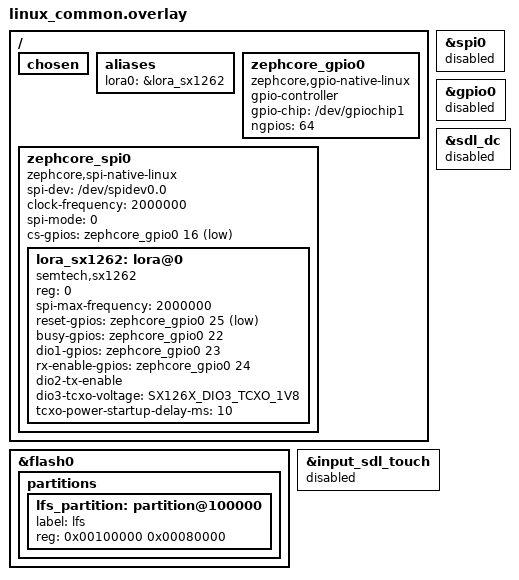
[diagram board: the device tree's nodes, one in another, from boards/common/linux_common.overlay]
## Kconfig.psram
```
# SPDX-License-Identifier: Apache-2.0
#
# DT-driven PSRAM auto-enable for ESP32 boards.
#
# Upstream Zephyr's esp32*_wroom_n*r*.dtsi files override psram0 size when
# the chip variant has PSRAM stuffed (R-suffix in the Espressif part number).
# We auto-enable PSRAM whenever the DTS size is non-zero — the upstream
# Kconfig.spiram then auto-reads ESP_SPIRAM_SIZE from the same DT property.
#
# Boards without PSRAM include a non-R-suffix dtsi (e.g. esp32s3_wroom_n8),
# which leaves psram0 at size = 0 — auto-detect leaves PSRAM off for them.
# ESP32-C3 and ESP32-C6 are outside Kconfig.spiram's SOC gate entirely, so
# this symbol doesn't exist on those builds — no effect.
#
# Mode (QUAD vs OCT) cannot be auto-picked here: upstream Kconfig.spiram
# sets an unconditional `default SPIRAM_MODE_QUAD` on the choice, which wins
# over any conditional default we'd add. ESP32-S3 R8 boards (8 MB OPI octal
# PSRAM) must set CONFIG_SPIRAM_MODE_OCT=y in their board.conf. R2 boards
# (2 MB QSPI quad) need nothing — QUAD is the upstream default.

config ESP_SPIRAM
	default y if (SOC_SERIES_ESP32 || SOC_SERIES_ESP32S2 || SOC_SERIES_ESP32S3 || SOC_SERIES_ESP32C5) && \
		"$(dt_node_int_prop_int,$(dt_nodelabel_path,psram0),size)" != 0
```

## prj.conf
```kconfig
# ZephCore - Main Project Configuration
#
# This file contains ONLY console/logging setup and includes common configs.
# Platform-specific configs are in boards/common/<platform>_common.conf
# Board-specific configs (pins only) are in boards/<board>.conf
#
# Include hierarchy:
#   prj.conf (this file - logging/console)
#   → boards/common/zephcore_common.conf (app features, crypto, sensors)
#   → boards/common/<platform>_common.conf (BLE, flash, storage)
#   → boards/<board>.conf (pins, board-specific features)

# ========== Console & Logging ==========
CONFIG_CONSOLE=y
CONFIG_UART_CONSOLE=y
CONFIG_UART_INTERRUPT_DRIVEN=y
CONFIG_RING_BUFFER=y

# Production by default — add boards/common/debug.conf to enable logging.
CONFIG_LOG=n
CONFIG_ASSERT=n
CONFIG_USE_SEGGER_RTT=n
CONFIG_THREAD_NAME=n

# Reboot on any fatal error (stack overflow, hard fault, etc.) instead of
# spinning forever. Asserts are disabled so they won't reach here, but all
# other fatal paths (k_panic, CPU exceptions) still get a clean reboot.
CONFIG_RESET_ON_FATAL_ERROR=y

# ========== Power Management ==========
# Note: nRF52840 automatically uses WFI (Wait For Interrupt) in idle thread.
# Power savings come from event-driven design: CPU sleeps in WFI whenever
# k_event_wait() blocks. GPS standby uses GPIO power control (not PM_DEVICE).
# CONFIG_PM_DEVICE intentionally DISABLED — it enables SYSTEM_MANAGED PM which
# auto-suspends all devices (including GNSS) during idle, calling modem_chat
# from an unexpected context and potentially deadlocking the system.
```

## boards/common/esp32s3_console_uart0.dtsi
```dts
/*
 * Reroute console + shell off USB Serial/JTAG onto uart0 (physical TX/RX).
 *
 * ESP32-S3 USB Serial/JTAG shares the D+/D- pins with USB OTG and only one
 * controller can own the port at a time.  Boards that default their console to
 * USB Serial/JTAG include this alongside esp32s3_usb_otg.dtsi so that, when
 * esp32s3_usb.conf disables USB Serial/JTAG and hands the port to USB OTG, the
 * console still has a home.  Boards with a dedicated UART console (e.g. Heltec)
 * do not need this.
 *
 * uart0 is disabled by default in the ESP32-S3 SoC dtsi, so we enable it and
 * pin it to the chip's ROM-default UART0 pads (GPIO43 TX / GPIO44 RX) — the
 * same pins Heltec uses.  Without this the console would point at a disabled,
 * un-pinned node and produce no output at all.
 */
#include <zephyr/dt-bindings/pinctrl/esp-pinctrl-common.h>
#include <zephyr/dt-bindings/pinctrl/esp32s3-pinctrl.h>
#include <zephyr/dt-bindings/pinctrl/esp32s3-gpio-sigmap.h>

&pinctrl {
	uart0_default: uart0_default {
		group1 {
			pinmux = <UART0_TX_GPIO43>;
			output-high;
		};
		group2 {
			pinmux = <UART0_RX_GPIO44>;
			bias-pull-up;
		};
	};
};

&uart0 {
	status = "okay";
	current-speed = <115200>;
	pinctrl-0 = <&uart0_default>;
	pinctrl-names = "default";
};

/ {
	chosen {
		zephyr,console    = &uart0;
		zephyr,shell-uart = &uart0;
	};
};
```

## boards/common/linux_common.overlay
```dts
/*
 * SPDX-License-Identifier: Apache-2.0
 *
 * ZephCore native Linux DT overlay (auto-paired with linux_common.conf).
 *
 * Disables the native_sim emulated GPIO/SPI controllers and adds our
 * libgpiod/spidev-backed native_linux versions, with an SX1262 child
 * node on the SPI bus.
 *
 * Generic defaults below match the Femtofox SX1262 wiring. Override per
 * device by adding boards/common/<device>.conf + .overlay via
 * EXTRA_CONF_FILE, or use --lora-* command-line args at runtime.
 */

#include <zephyr/dt-bindings/gpio/gpio.h>
#include <zephyr/dt-bindings/lora/sx126x.h>

/* Disable native_sim emulated controllers (replaced below). */
&spi0 {
	status = "disabled";
};

&gpio0 {
	status = "disabled";
};

/* LittleFS on native_sim's simulated flash.
 * The native_sim board DTS allocates the first 1MB (0x0..0xfffff) for
 * MCUBoot + OTA slots. The second half (0x100000..0x1fffff = 1MB) is unused.
 * Use 512KB of it for LittleFS — 128 × 4KB blocks, plenty for identity,
 * prefs, contacts, and channels.
 * The sim-flash is in-memory (lost on exit); add
 * CONFIG_FLASH_SIMULATOR_STATS_FILE for file-backed persistence. */
&flash0 {
	partitions {
		lfs_partition: partition@100000 {
			label = "lfs";
			reg = <0x00100000 0x00080000>; /* 512 KB */
		};
	};
};

#include "filesystem.dtsi"

/* Disable the SDL emulated display + touch (we don't use them and the
 * SDL2 dev library isn't a useful dep on a headless SBC). */
&sdl_dc {
	status = "disabled";
};

&input_sdl_touch {
	status = "disabled";
};

/* Drop the chosen zephyr,display node so HAS_SDL doesn't get selected.
 * Also drop the led0 alias — native_sim's base DTS attaches it to the
 * emulated gpio0 that we just disabled, which would otherwise cause a
 * dangling DEVICE_DT_GET in helpers/ui/ui_common.c. */
/ {
	chosen {
		/delete-property/ zephyr,display;
		/delete-property/ zephyr,touch;
	};
	aliases {
		/delete-property/ led0;
	};
};

/ {
	/delete-node/ leds;
};

/ {
	aliases {
		/* The mesh adapter reads lora0 alias to bind the SX126x driver. */
		lora0 = &lora_sx1262;
	};

	/* libgpiod v2 GPIO controller bound to a host /dev/gpiochipX. */
	zephcore_gpio0: zephcore_gpio0 {
		status = "okay";
		compatible = "zephcore,gpio-native-linux";
		gpio-controller;
		gpio-chip = "/dev/gpiochip1";
		ngpios = <64>;
		#gpio-cells = <2>;
	};

	/* spidev-backed SPI bus on /dev/spidev0.0 with one SX1262 child. */
	zephcore_spi0: zephcore_spi0 {
		status = "okay";
		compatible = "zephcore,spi-native-linux";
		spi-dev = "/dev/spidev0.0";
		clock-frequency = <2000000>;
		spi-mode = <0>;
		#address-cells = <1>;
		#size-cells = <0>;
		/* CS line: GPIO 16 on chip 1 = GPIO48 = 1C0 (Femtofox default). */
		cs-gpios = <&zephcore_gpio0 16 GPIO_ACTIVE_LOW>;

		lora_sx1262: lora@0 {
			compatible = "semtech,sx1262";
			reg = <0>;
			spi-max-frequency = <2000000>;
			/* Femtofox defaults; overridden by per-device overlays. */
			reset-gpios = <&zephcore_gpio0 25 GPIO_ACTIVE_LOW>;
			busy-gpios  = <&zephcore_gpio0 22 GPIO_ACTIVE_HIGH>;
			dio1-gpios  = <&zephcore_gpio0 23 GPIO_ACTIVE_HIGH>;
			rx-enable-gpios = <&zephcore_gpio0 24 GPIO_ACTIVE_HIGH>;
			dio2-tx-enable;
			dio3-tcxo-voltage = <SX126X_DIO3_TCXO_1V8>;
			tcxo-power-startup-delay-ms = <10>;
		};
	};
};
```

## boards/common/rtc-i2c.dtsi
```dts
/*
 * Common I2C Real-Time-Clock descriptors for ZephCore
 * SPDX-License-Identifier: Apache-2.0
 *
 * OPT-IN: include this inside an &i2cN { ... } block ONLY on boards that
 * physically have a battery/cap-backed RTC. Kept separate from
 * sensors-i2c.dtsi because these declare fixed I2C addresses (0x68/0x51/
 * 0x52/0x32) that collide with common parts — an IMU/accelerometer sits at
 * 0x68 (same as DS3231). Including this on a board without an RTC would risk
 * a devicetree unit-address clash and a runtime mis-probe, so it is opt-in.
 *
 * Usage (board overlay/dts, alongside the sensors include):
 *   &i2c0 {
 *       #include "../../common/sensors-i2c.dtsi"
 *       #include "../../common/rtc-i2c.dtsi"
 *   };
 *
 * These bind NO Zephyr RTC driver — they're data-only descriptors the
 * boot-time auto-discovery (adapters/clock/ZephyrRTCDiscover.c) probes via
 * raw I2C to restore wall-clock time at boot. A chip that isn't actually
 * present fails the probe and is skipped. One chip per I2C address:
 *
 *  Chip      │ Addr │ Also covers (same regs)
 *  ──────────┼──────┼─────────────────────────
 *  DS3231    │ 0x68 │ DS1307, DS3232
 *  PCF8563   │ 0x51 │ —   (PCF85063A is 0x51 too but differs — override)
 *  RV3028    │ 0x52 │ —
 *  RX8130CE  │ 0x32 │ —   (RV8803 is 0x32 too but differs — override)
 *
 * status-reg 0xFF means the power-loss flag is in the seconds byte. A board
 * with a same-address variant should /delete-node/ the conflicting one and
 * add its own in the board overlay.
 */

rtc_ds3231: rtc-ds3231@68 {
	compatible = "zephcore,rtc-i2c";
	reg = <0x68>;
	time-reg = <0x00>;
	date-index = <4>;
	status-reg = <0x0F>;   /* control/status */
	status-mask = <0x80>;  /* OSF — oscillator stopped */
};

rtc_pcf8563: rtc-pcf8563@51 {
	compatible = "zephcore,rtc-i2c";
	reg = <0x51>;
	time-reg = <0x02>;
	date-index = <3>;      /* PCF8563 puts date before weekday */
	status-reg = <0xFF>;   /* flag is in the seconds byte */
	status-mask = <0x80>;  /* VL — clock integrity not guaranteed */
};

rtc_rv3028: rtc-rv3028@52 {
	compatible = "zephcore,rtc-i2c";
	reg = <0x52>;
	time-reg = <0x00>;
	date-index = <4>;
	status-reg = <0x0e>;   /* status */
	status-mask = <0x01>;  /* PORF — power-on reset */
};

rtc_rx8130ce: rtc-rx8130ce@32 {
	compatible = "zephcore,rtc-i2c";
	reg = <0x32>;
	time-reg = <0x10>;
	date-index = <4>;
	status-reg = <0x1d>;   /* flag */
	status-mask = <0x02>;  /* VLF — voltage low */
};
```

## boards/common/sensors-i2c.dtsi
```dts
/*
 * Common I2C Sensor Definitions for ZephCore
 * SPDX-License-Identifier: Apache-2.0
 *
 * Include this file inside an &i2cN { ... } block to define all
 * supported sensor nodes on that bus.  Sensors that are not physically
 * present will fail device_is_ready() at runtime and be gracefully
 * skipped by ZephyrEnvSensors — no harm, no extra current draw.
 *
 * Usage (board overlay):
 *   &i2c0 {
 *       #include "../../common/sensors-i2c.dtsi"
 *   };
 *
 * ─── Environment Sensors (temperature / humidity / pressure) ───
 *
 *  Sensor      │ Address │ Compatible          │ Channels
 *  ────────────┼─────────┼─────────────────────┼────────────────────
 *  SHTC3       │ 0x70    │ sensirion,shtcx     │ temp + humidity
 *  AHT20       │ 0x38    │ aosong,aht20        │ temp + humidity
 *  DHT20       │ 0x38    │ aosong,dht20        │ temp + humidity
 *  AM2301B     │ 0x38    │ aosong,am2301b      │ temp + humidity
 *  SHT4x       │ 0x44    │ sensirion,sht4x     │ temp + humidity
 *  SHT3xD      │ 0x44    │ sensirion,sht3xd    │ temp + humidity
 *  BME280      │ 0x76    │ bosch,bme280        │ temp + humidity + pressure
 *  BME680      │ 0x76    │ bosch,bme680        │ temp + humidity + pressure + gas
 *  BMP280      │ 0x77    │ bosch,bme280        │ temp + pressure (BME280 driver)
 *  BMP388      │ 0x77    │ bosch,bmp388        │ temp + pressure
 *  LPS22HB     │ 0x5C    │ st,lps22hb-press    │ pressure + temp
 *
 *  Note: AHT20/DHT20/AM2301B share address 0x38 — only one can be
 *  defined.  We use AHT20 as the default (same driver handles all).
 *
 *  Note: SHT4x and SHT3xD share address 0x44 — only one can be
 *  defined.  We use SHT4x as the default (more common in new designs).
 *
 *  Note: BME280 and BME680 share address 0x76 — only one can be
 *  defined.  We use BME280 as default (its driver also handles BMP280).
 *  Boards with BME680 should override this node in their overlay.
 *
 *  Note: BMP280 uses the BME280 driver (same register set), at alt
 *  address 0x77.  BMP388 also uses 0x77.  Only one can be defined —
 *  we use BMP388 since it's the newer part.
 *
 * ─── Power Monitor Sensors (voltage / current / power) ───
 *
 *  Sensor      │ Address │ Compatible   │ Channels
 *  ────────────┼─────────┼──────────────┼────────────────────
 *  INA219      │ 0x40    │ ti,ina219    │ 1ch: V + I + P
 *  INA3221     │ 0x40    │ ti,ina3221   │ 3ch: V + I + P
 *  INA226      │ 0x40    │ ti,ina226    │ 1ch: V + I + P
 *
 *  Note: INA219, INA3221, and INA226 share address 0x40 — only one
 *  can be defined at a time.  Boards with a specific INA chip should
 *  delete the others or override this file.
 *  We define INA219 as default (most common single-channel monitor).
 */

/* ── Temperature / Humidity ── */

shtc3: shtc3@70 {
	compatible = "sensirion,shtcx";
	reg = <0x70>;
	measure-mode = "normal";
	clock-stretching;
};

aht20: aht20@38 {
	compatible = "aosong,aht20";
	reg = <0x38>;
};

sht4x: sht4x@44 {
	compatible = "sensirion,sht4x";
	reg = <0x44>;
	repeatability = <2>;  /* high */
};

/* ── Combo: Temperature + Humidity + Pressure ── */

bme280: bme280@76 {
	compatible = "bosch,bme280";
	reg = <0x76>;
};

/* ── Pressure (standalone) ── */

lps22hb: lps22hb@5c {
	compatible = "st,lps22hb-press";
	reg = <0x5c>;
};

bmp388: bmp388@77 {
	compatible = "bosch,bmp388";
	reg = <0x77>;
};

/* ── Power Monitors ── */

ina219: ina219@40 {
	compatible = "ti,ina219";
	reg = <0x40>;
	shunt-milliohm = <100>;
	lsb-microamp = <10>;
};

/* Real-time clocks are NOT here — they live in the opt-in "rtc-i2c.dtsi"
 * (included only by boards that physically have a battery-backed RTC), so
 * their fixed addresses (0x68/0x51/0x52/0x32) can't collide with an IMU or
 * other peripheral on boards that don't. */
```

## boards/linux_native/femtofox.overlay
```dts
/*
 * SPDX-License-Identifier: Apache-2.0
 *
 * Femtofox (Luckfox Pico Mini RV1103 + Ebyte E22-900M30S, SX1262 TCXO) wiring.
 * Auto-paired with femtofox.conf. Defines the native_linux SPI/GPIO controllers
 * and the SX1262 radio node on top of the platform infra in linux_common.overlay.
 *
 * Pins match the meshtasticd Femtofox profile (femtofox_SX1262_TCXO.yaml):
 * gpiochip1, CS=16/GPIO48, BUSY=22/GPIO54, DIO1=23/GPIO55, RESET=25/GPIO57,
 * RXEN=24/GPIO56. DIO2 drives the RF switch, DIO3 powers a 1.8V TCXO.
 */

#include <zephyr/dt-bindings/gpio/gpio.h>
#include <zephyr/dt-bindings/lora/sx126x.h>

/ {
	aliases {
		/* The mesh adapter reads lora0 to bind the SX126x driver. */
		lora0 = &lora_sx1262;
	};

	/* GPIO V2 chardev controller bound to /dev/gpiochip1. */
	zephcore_gpio0: zephcore_gpio0 {
		status = "okay";
		compatible = "zephcore,gpio-native-linux";
		gpio-controller;
		gpio-chip = "/dev/gpiochip1";
		ngpios = <64>;
		#gpio-cells = <2>;
	};

	/* spidev-backed SPI bus on /dev/spidev0.0 with one SX1262 child. */
	zephcore_spi0: zephcore_spi0 {
		status = "okay";
		compatible = "zephcore,spi-native-linux";
		spi-dev = "/dev/spidev0.0";
		clock-frequency = <2000000>;
		spi-mode = <0>;
		#address-cells = <1>;
		#size-cells = <0>;
		/* CS: gpiochip1 offset 16 = GPIO48. */
		cs-gpios = <&zephcore_gpio0 16 GPIO_ACTIVE_LOW>;

		lora_sx1262: lora@0 {
			compatible = "semtech,sx1262";
			reg = <0>;
			spi-max-frequency = <2000000>;
			reset-gpios = <&zephcore_gpio0 25 GPIO_ACTIVE_LOW>;
			busy-gpios  = <&zephcore_gpio0 22 GPIO_ACTIVE_HIGH>;
			dio1-gpios  = <&zephcore_gpio0 23 GPIO_ACTIVE_HIGH>;
			rx-enable-gpios = <&zephcore_gpio0 24 GPIO_ACTIVE_HIGH>;
			dio2-tx-enable;
			dio3-tcxo-voltage = <SX126X_DIO3_TCXO_1V8>;
			tcxo-power-startup-delay-ms = <5>;
		};
	};
};
```

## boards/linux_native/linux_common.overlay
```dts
/*
 * SPDX-License-Identifier: Apache-2.0
 *
 * ZephCore native Linux PLATFORM overlay (auto-paired with linux_common.conf,
 * applied automatically for BOARD=native_sim).
 *
 * Platform infrastructure ONLY — it disables native_sim's emulated SPI/GPIO
 * and SDL display, and sets up the LittleFS partition. The radio wiring and
 * the native_linux SPI/GPIO controller nodes live in the per-device preset
 * overlay (femtofox.overlay, rak6421.overlay, rak6421_pi5.overlay).
 *
 * You MUST pass a device preset via EXTRA_CONF_FILE, e.g.
 *   -DEXTRA_CONF_FILE="boards/linux_native/femtofox.conf"
 * A bare `-b native_sim` build with no device preset has no SX1262 node and
 * will fail to link the radio adapter (no `lora0` alias).
 */

/* Disable the native_sim emulated controllers — each device preset adds its
 * own zephcore_spi0 / zephcore_gpio0 backed by real /dev/spidev* + /dev/gpiochip*. */
&spi0 {
	status = "disabled";
};

&gpio0 {
	status = "disabled";
};

/* LittleFS on native_sim's simulated flash.
 * The native_sim board DTS allocates the first 1MB (0x0..0xfffff) for
 * MCUBoot + OTA slots. The second half (0x100000..0x1fffff = 1MB) is unused;
 * use 512KB of it for LittleFS — 128 × 4KB blocks, plenty for identity,
 * prefs, contacts, and channels.
 * The sim-flash is FILE-BACKED on native_sim (ARCH_POSIX): it persists across
 * restarts in meshcore_settings_<hostname>.bin in the binary's working dir
 * (see patches/zephyr/0008-flash-sim-per-node-file.patch). Pass --flash=<path>
 * to override, or --flash_in_ram to make it ephemeral. */
&flash0 {
	partitions {
		lfs_partition: partition@100000 {
			label = "lfs";
			reg = <0x00100000 0x00080000>; /* 512 KB */
		};
	};
};

#include "../common/filesystem.dtsi"

/* Disable the SDL emulated display + touch (headless SBC; the SDL2 dev library
 * isn't a useful dep, and HAS_SDL would otherwise get selected). */
&sdl_dc {
	status = "disabled";
};

&input_sdl_touch {
	status = "disabled";
};

/ {
	chosen {
		/delete-property/ zephyr,display;
		/delete-property/ zephyr,touch;
	};
	aliases {
		/* native_sim's base DTS attaches led0 to the emulated gpio0 we just
		 * disabled; drop it so helpers/ui/ui_common.c has no dangling
		 * DEVICE_DT_GET. */
		/delete-property/ led0;
	};
};

/ {
	/delete-node/ leds;
};
```

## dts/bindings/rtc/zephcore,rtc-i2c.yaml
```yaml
# SPDX-License-Identifier: Apache-2.0
#
# Data-only descriptor for an I2C RTC chip read by ZephyrRTCDiscover
# (adapters/clock/ZephyrRTCDiscover.c). This binds NO Zephyr RTC driver —
# the chip is accessed with raw I2C using the register layout described by
# the properties below. This keeps the boot-time RTC restore compact
# (~2-3 KB total, "Path B") instead of pulling in the full RTC subsystem.
#
# All supported chips use a 7-byte BCD time block (sec, min, hour, then
# weekday/date, month, year) starting at "time-reg". Only the day-of-month
# byte offset varies between parts, captured by "date-index".

description: ZephCore data-only I2C RTC descriptor (raw-I2C, no Zephyr RTC driver)

compatible: "zephcore,rtc-i2c"

include: [i2c-device.yaml]

properties:
  time-reg:
    type: int
    required: true
    description: Register address of the seconds byte (start of the 7-byte BCD block).

  date-index:
    type: int
    required: true
    description: >
      Byte offset of the day-of-month within the 7-byte block. 4 for chips
      ordered sec/min/hour/weekday/date/month/year (DS3231, RV3028, RX8130CE);
      3 for PCF8563 which swaps to sec/min/hour/date/weekday/month/year.

  status-reg:
    type: int
    required: true
    description: >
      Register holding the "time invalid / power was lost" flag. Use 0xFF to
      indicate the flag lives in the seconds byte itself (PCF8563 VL bit).

  status-mask:
    type: int
    required: true
    description: Bit mask within status-reg that means the held time is unreliable.
```

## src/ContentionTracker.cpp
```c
/*
 * SPDX-License-Identifier: Apache-2.0
 * Adaptive Contention Window — dupe-counting based delay estimation
 */

#include <mesh/ContentionTracker.h>
#include <mesh/Packet.h>
#include <string.h>

namespace mesh {

ContentionTracker::ContentionTracker()
	: _next_idx(0), _ema_x256(0), _finalized_count(0),
	  _last_retransmit_ms(0), _backoff_multiplier(DEFAULT_BACKOFF_MULT)
{
	memset(_ring, 0, sizeof(_ring));
}

/* FNV-1a over payload_type + first 8 payload bytes */
uint32_t ContentionTracker::computePacketHash32(const Packet *pkt)
{
	uint32_t h = 0x811c9dc5u; /* FNV-1a offset basis */
	uint8_t t = pkt->getPayloadType();
	h = (h ^ t) * 0x01000193u;
	int n = pkt->payload_len < 8 ? pkt->payload_len : 8;
	for (int i = 0; i < n; i++) {
		h = (h ^ pkt->payload[i]) * 0x01000193u;
	}
	return h;
}

int ContentionTracker::findEntry(uint32_t hash32) const
{
	for (int i = 0; i < RING_SIZE; i++) {
		if (_ring[i].active && _ring[i].hash32 == hash32) {
			return i;
		}
	}
	return -1;
}

void ContentionTracker::finalizeEntry(int idx)
{
	if (!_ring[idx].active) return;

	uint32_t sample_x256 = (uint32_t)_ring[idx].dupe_count << 8;

	int32_t diff = (int32_t)sample_x256 - (int32_t)_ema_x256;

	if (_finalized_count < WARMUP_PACKETS) {
		/* Warmup: seed EMA with fast convergence */
		if (_finalized_count == 0) {
			_ema_x256 = sample_x256;
		} else {
			_ema_x256 = (uint32_t)((int32_t)_ema_x256 + (diff >> 1));
		}
	} else {
		_ema_x256 = (uint32_t)((int32_t)_ema_x256 + (diff >> EMA_SHIFT));
	}

	_finalized_count++;
	_ring[idx].active = false;
}

void ContentionTracker::trackRetransmit(uint32_t hash32, uint32_t now_ms)
{
	_last_retransmit_ms = now_ms;

	/* Evict oldest if ring slot occupied */
	if (_ring[_next_idx].active) {
		finalizeEntry(_next_idx);
	}

	Entry &e = _ring[_next_idx];
	e.hash32 = hash32;
	e.first_seen_ms = now_ms;
	e.dupe_count = 0;
	e.reactive_added_ms = 0;
	e.active = true;

	_next_idx = (_next_idx + 1) % RING_SIZE;
}

bool ContentionTracker::recordDupeIfTracked(uint32_t hash32, uint32_t now_ms)
{
	int idx = findEntry(hash32);
	if (idx < 0) return false;

	Entry &e = _ring[idx];

	if (now_ms - e.first_seen_ms > WINDOW_MS) {
		finalizeEntry(idx);
		return false;
	}

	if (e.dupe_count < 255) {
		e.dupe_count++;
	}
	return true;
}

int ContentionTracker::extractDupeCount(uint32_t hash32)
{
	int idx = findEntry(hash32);
	if (idx < 0) return -1;
	int count = (int)_ring[idx].dupe_count;
	finalizeEntry(idx);  /* folds into EMA, marks inactive */
	return count;
}

uint16_t ContentionTracker::getReactiveHeadroom(uint32_t hash32, uint32_t airtime_ms) const
{
	int idx = findEntry(hash32);
	if (idx < 0) return 0;

	uint32_t per_dupe = (uint32_t)(_backoff_multiplier * (float)airtime_ms);
	if (per_dupe == 0) return 0;

	/* Effective cap: ~12 relay-slots (airtime-scaled), absolute ceiling REACTIVE_HARD_CAP_MS */
	uint32_t effective_cap = 12 * airtime_ms;
	if (effective_cap > REACTIVE_HARD_CAP_MS) effective_cap = REACTIVE_HARD_CAP_MS;

	if (_ring[idx].reactive_added_ms >= effective_cap) return 0;

	uint32_t remaining = effective_cap - _ring[idx].reactive_added_ms;
	if (per_dupe > remaining) per_dupe = remaining;
	return per_dupe > 0xFFFF ? 0xFFFF : (uint16_t)per_dupe;
}

void ContentionTracker::addReactiveExtension(uint32_t hash32, uint16_t added_ms)
{
	int idx = findEntry(hash32);
	if (idx < 0) return;

	uint32_t total = (uint32_t)_ring[idx].reactive_added_ms + added_ms;
	_ring[idx].reactive_added_ms = total > 0xFFFF ? 0xFFFF : (uint16_t)total;
}

void ContentionTracker::tick(uint32_t now_ms)
{
	for (int i = 0; i < RING_SIZE; i++) {
		if (_ring[i].active && now_ms - _ring[i].first_seen_ms > WINDOW_MS) {
			finalizeEntry(i);
		}
	}

	/* Decay EMA toward 0 if no retransmit in STALE_MS */
	if (_last_retransmit_ms != 0 && now_ms - _last_retransmit_ms > STALE_MS) {
		if (_ema_x256 > 0) {
			_ema_x256 -= _ema_x256 >> EMA_SHIFT;
		}
	}
}

float ContentionTracker::getContentionEstimate() const
{
	return (float)_ema_x256 / 256.0f;
}

float ContentionTracker::getFloodDelayFactor() const
{
	if (!isWarmedUp()) return 0.5f; /* conservative default before warmup */

	float est = getContentionEstimate();
	if (est <= 0.0f) return MIN_FLOOD_FACTOR;

	/* Arduino-like center near 0.5 in light contention, rising smoothly
	 * toward 0.8 as contention increases. */
	float factor = MIN_FLOOD_FACTOR + (MAX_FLOOD_FACTOR - MIN_FLOOD_FACTOR) *
		       (est / (est + FLOOD_EST_HALFPOINT));
	if (factor > MAX_FLOOD_FACTOR) factor = MAX_FLOOD_FACTOR;
	return factor;
}

} /* namespace mesh */
```

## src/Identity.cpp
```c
/*
 * SPDX-License-Identifier: Apache-2.0
 * ZephCore Identity - Ed25519 sign/verify (Monocypher backend)
 *
 * Backed by Monocypher (lib/monocypher). The persisted private key keeps the
 * historical 64-byte *expanded* layout — prv[0..31] = clamped SHA-512(seed)
 * scalar `a`, prv[32..63] = nonce prefix — so identities written by older
 * (orlp/ed25519) firmware load, sign, and key-exchange byte-for-byte unchanged.
 * Signing is built from Monocypher's low-level EdDSA primitives because the
 * stored expanded key carries no seed to feed the high-level API.
 */

#include <mesh/Identity.h>
#include <string.h>
#include <monocypher.h>
#include <monocypher-ed25519.h>

namespace mesh {

/* Expand a 32-byte seed into the stored 64-byte private key (orlp-compatible
 * layout): clamped SHA-512(seed)[0..31] || SHA-512(seed)[32..63]. */
static void expandSeed(uint8_t prv[PRV_KEY_SIZE], const uint8_t seed[SEED_SIZE])
{
	crypto_sha512(prv, seed, SEED_SIZE);
	prv[0]  &= 248;
	prv[31] &= 63;
	prv[31] |= 64;
}

/* Sign from the expanded key (no seed). RFC 8032 Ed25519 assembled from
 * Monocypher scalar/point primitives — byte-identical to the prior orlp
 * implementation (verified by known-answer tests). */
static void signExpanded(uint8_t sig[SIGNATURE_SIZE],
			 const uint8_t prv[PRV_KEY_SIZE],
			 const uint8_t pub[PUB_KEY_SIZE],
			 const uint8_t *msg, size_t msg_len)
{
	uint8_t r64[64], hram64[64], r[32], hram[32];
	crypto_sha512_ctx h;

	/* r = SHA-512(prefix || msg) mod L ; prefix = prv[32..63] */
	crypto_sha512_init(&h);
	crypto_sha512_update(&h, prv + 32, 32);
	crypto_sha512_update(&h, msg, msg_len);
	crypto_sha512_final(&h, r64);
	crypto_eddsa_reduce(r, r64);

	/* R = r·B -> sig[0..31] */
	crypto_eddsa_scalarbase(sig, r);

	/* hram = SHA-512(R || A || msg) mod L */
	crypto_sha512_init(&h);
	crypto_sha512_update(&h, sig, 32);
	crypto_sha512_update(&h, pub, 32);
	crypto_sha512_update(&h, msg, msg_len);
	crypto_sha512_final(&h, hram64);
	crypto_eddsa_reduce(hram, hram64);

	/* S = (hram·a + r) mod L ; a = prv[0..31] -> sig[32..63] */
	crypto_eddsa_mul_add(sig + 32, hram, prv, r);

	/* r / r64 are nonce material — leaking them leaks the private key. */
	crypto_wipe(r64, sizeof(r64));
	crypto_wipe(r, sizeof(r));
}

/* X25519 over Ed25519 keys: convert the peer's Edwards public key to its
 * Montgomery form, then scalar-multiply by our scalar (prv[0..31]). Raw
 * shared secret, no output hashing — matches the prior orlp key_exchange. */
static void calcECDH(uint8_t secret[CIPHER_KEY_SIZE * 2],
		     const uint8_t prv[PRV_KEY_SIZE],
		     const uint8_t other_pub[PUB_KEY_SIZE])
{
	uint8_t other_x[32];
	crypto_eddsa_to_x25519(other_x, other_pub);
	crypto_x25519(secret, prv, other_x);
}

Identity::Identity()
{
	memset(pub_key, 0, sizeof(pub_key));
}

Identity::Identity(const char *pub_hex)
{
	Utils::fromHex(pub_key, PUB_KEY_SIZE, pub_hex);
}

bool Identity::verify(const uint8_t *sig, const uint8_t *message, int msg_len) const
{
	return crypto_ed25519_check(sig, pub_key, message, (size_t)msg_len) == 0;
}

bool Identity::readFrom(const uint8_t *src, size_t len)
{
	if (len < PUB_KEY_SIZE) return false;
	memcpy(pub_key, src, PUB_KEY_SIZE);
	return true;
}

bool Identity::writeTo(uint8_t *dest, size_t max_len) const
{
	if (max_len < PUB_KEY_SIZE) return false;
	memcpy(dest, pub_key, PUB_KEY_SIZE);
	return true;
}

LocalIdentity::LocalIdentity()
{
	memset(prv_key, 0, sizeof(prv_key));
}

LocalIdentity::LocalIdentity(const char *prv_hex, const char *pub_hex) : Identity(pub_hex)
{
	Utils::fromHex(prv_key, PRV_KEY_SIZE, prv_hex);
}

LocalIdentity::LocalIdentity(RNG *rng)
{
	uint8_t seed[SEED_SIZE];
	rng->random(seed, SEED_SIZE);
	fromSeed(seed);
	Utils::secureZeroize(seed, sizeof(seed));
}

void LocalIdentity::fromSeed(const uint8_t seed[SEED_SIZE])
{
	expandSeed(prv_key, seed);
	crypto_eddsa_scalarbase(pub_key, prv_key);  /* pub = a·B */
}

bool LocalIdentity::validatePrivateKey(const uint8_t prv[64])
{
	uint8_t pub[32];
	crypto_eddsa_scalarbase(pub, prv);
	if (pub[0] == 0x00 || pub[0] == 0xFF) return false;

	const uint8_t test_client_prv[64] = {
		0x70, 0x65, 0xe1, 0x8f, 0xd9, 0xfa, 0xbb, 0x70,
		0xc1, 0xed, 0x90, 0xdc, 0xa1, 0x99, 0x07, 0xde,
		0x69, 0x8c, 0x88, 0xb7, 0x09, 0xea, 0x14, 0x6e,
		0xaf, 0xd9, 0x3d, 0x9b, 0x83, 0x0c, 0x7b, 0x60,
		0xc4, 0x68, 0x11, 0x93, 0xc7, 0x9b, 0xbc, 0x39,
		0x94, 0x5b, 0xa8, 0x06, 0x41, 0x04, 0xbb, 0x61,
		0x8f, 0x8f, 0xd7, 0xa8, 0x4a, 0x0a, 0xf6, 0xf5,
		0x70, 0x33, 0xd6, 0xe8, 0xdd, 0xcd, 0x64, 0x71
	};
	const uint8_t test_client_pub[32] = {
		0x1e, 0xc7, 0x71, 0x75, 0xb0, 0x91, 0x8e, 0xd2,
		0x06, 0xf9, 0xae, 0x04, 0xec, 0x13, 0x6d, 0x6d,
		0x5d, 0x43, 0x15, 0xbb, 0x26, 0x30, 0x54, 0x27,
		0xf6, 0x45, 0xb4, 0x92, 0xe9, 0x35, 0x0c, 0x10
	};

	uint8_t ss1[32], ss2[32];
	calcECDH(ss1, prv, test_client_pub);
	calcECDH(ss2, test_client_prv, pub);
	/* Constant-time even though this self-test runs at boot before
	 * any networking is up — hygiene + no attacker observation. */
	if (!Utils::constantTimeEqual(ss1, ss2, 32)) {
		Utils::secureZeroize(ss1, sizeof(ss1));
		Utils::secureZeroize(ss2, sizeof(ss2));
		return false;
	}

	bool nonzero = false;
	for (int i = 0; i < 32; i++) {
		if (ss1[i] != 0) { nonzero = true; break; }
	}
	Utils::secureZeroize(ss1, sizeof(ss1));
	Utils::secureZeroize(ss2, sizeof(ss2));
	return nonzero;
}

bool LocalIdentity::readFrom(const uint8_t *src, size_t len)
{
	if (len == PRV_KEY_SIZE + PUB_KEY_SIZE) {
		memcpy(prv_key, src, PRV_KEY_SIZE);
		memcpy(pub_key, src + PRV_KEY_SIZE, PUB_KEY_SIZE);
		return true;
	}
	if (len == PRV_KEY_SIZE) {
		memcpy(prv_key, src, PRV_KEY_SIZE);
		crypto_eddsa_scalarbase(pub_key, prv_key);  /* derive pub from a */
		return true;
	}
	return false;
}

size_t LocalIdentity::writeTo(uint8_t *dest, size_t max_len) const
{
	if (max_len < PRV_KEY_SIZE) return 0;
	if (max_len < PRV_KEY_SIZE + PUB_KEY_SIZE) {
		memcpy(dest, prv_key, PRV_KEY_SIZE);
		return PRV_KEY_SIZE;
	}
	memcpy(dest, prv_key, PRV_KEY_SIZE);
	memcpy(dest + PRV_KEY_SIZE, pub_key, PUB_KEY_SIZE);
	return PRV_KEY_SIZE + PUB_KEY_SIZE;
}

void LocalIdentity::sign(uint8_t *sig, const uint8_t *message, int msg_len) const
{
	signExpanded(sig, prv_key, pub_key, message, (size_t)msg_len);
}

void LocalIdentity::calcSharedSecret(uint8_t *secret, const uint8_t *other_pub_key) const
{
	calcECDH(secret, prv_key, other_pub_key);
}

} /* namespace mesh */
```
